# PIC32CZ4010CA80144 register map
Vendor: Microchip Technology; Series: PIC32CZCA80; File version: 0
CPU: CM7 r1p1, little endian, MPU, FPU, double-precision FPU, I-cache, D-cache, ITCM, DTCM, 3 interrupt priority bits, 222 interrupts
Registers are 32-bit, read-write, reset 0x0 unless marked. A register's access mark holds for its fields unless they carry their own. Offsets are from the block's base; [hi:lo] are bit positions.

## FCR — Flash Read Controller (FCR)
Base 0x44004000
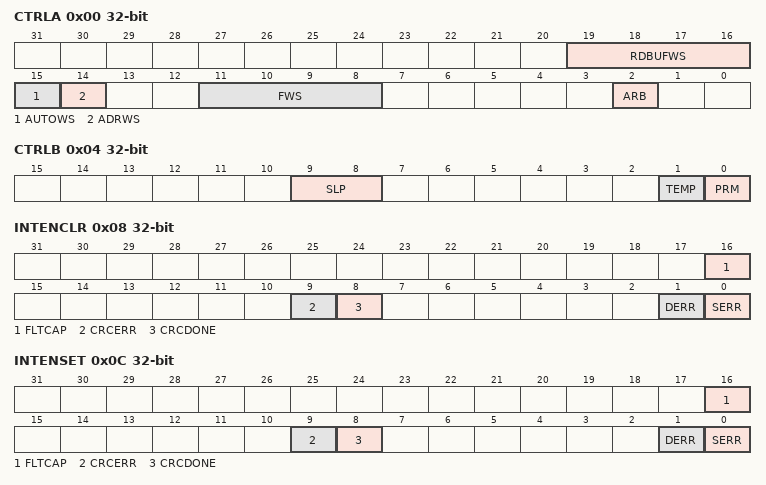
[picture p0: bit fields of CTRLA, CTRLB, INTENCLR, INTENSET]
0x00 CTRLA — Control A Register
  [19:16] RDBUFWS — Data returned from the Read Buffer match the Flash Wait States
  [15] AUTOWS — Automatic Wait State Enable.
  [14] ADRWS — Address Wait State Enable
  [11:8] FWS — Flash Access Time Defined in terms of AHB Clock Wait States
  [2] ARB — AHB Arbitration scheme
0x04 CTRLB — Control B Register
  [9:8] SLP — NVM Power Reduction Mode selection during System Standby Sleep
  [1] TEMP — NVM Operating Temperature Read Mode
  [0] PRM — Set NVM Power Reduction Mode
0x08 INTENCLR write-1-clears — Interrupt Enable Clear Register
  [16] FLTCAP — ECC Fault Capture Clear Enable
  [9] CRCERR — CRC Error Clear Enable
  [8] CRCDONE — CRC Calculation Done Clear Enable
  [1] DERR — ECC Double Error Detected Clear Enable
  [0] SERR — Flash SEC Interrupt Clear Enable
0x0C INTENSET write-1-sets — Interrupt Enable SET Register
  [16] FLTCAP — ECC Fault Capture Interrupt Set Enable
  [9] CRCERR — CRC Error Interrupt Set Enable
  [8] CRCDONE — CRC Calculation Done Set Enable
  [1] DERR — ECC Double Error Detected Set Enable
  [0] SERR — Flash Single Error Corrected Set Enable
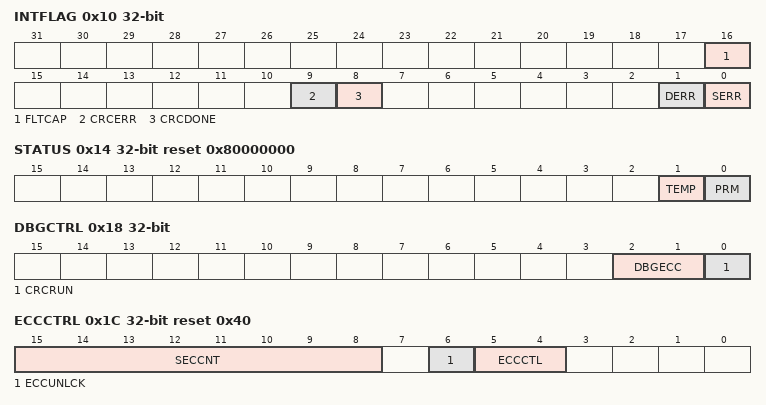
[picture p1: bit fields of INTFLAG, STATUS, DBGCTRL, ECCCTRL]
0x10 INTFLAG write-1-clears — Interrupt Flag Register
  [16] FLTCAP — ECC Fault Capture Flag
  [9] CRCERR — CRC Error Flag
  [8] CRCDONE — CRC Calculation Done Flag
  [1] DERR — ECC Double Error Detected Flag
  [0] SERR — Flash Single Error Corrected Flag
0x14 STATUS ro reset 0x80000000 — NVM Status Register
  [1] TEMP — NVM Operating Temperature Read Mode Status
  [0] PRM — NVM Power Reduction Mode Status
0x18 DBGCTRL — Debug Control Register
  [2:1] DBGECC — Debug ECC Mode
  [0] CRCRUN — CRC Debug Run
0x1C ECCCTRL reset 0x40 — ECC Control Register
  [15:8] SECCNT — Flash SEC Count
  [6] ECCUNLCK — NVM ECC Mode Control Unlock
  [5:4] ECCCTL — NVM ECC Mode Control- restricts one or more NVMOPs
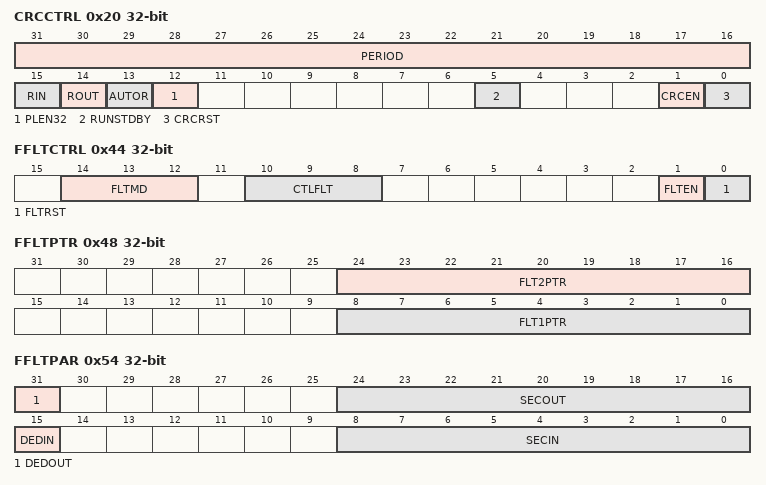
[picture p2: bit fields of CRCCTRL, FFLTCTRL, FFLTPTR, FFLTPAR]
0x20 CRCCTRL — CRC Control Register
  [31:16] PERIOD — Read Period in GCLK counts
  [15] RIN — CRC Reflected Input
  [14] ROUT — CRC Reflected Output
  [13] AUTOR — CRC Auto Repeat
  [12] PLEN32 — Polynomial Length Select
  [5] RUNSTDBY — CRC Run in Standby
  [1] CRCEN — Start CRC Calculation
  [0] CRCRST — CRC Reset
0x24 CRCPAUSE
  [0] PAUSE — CRC Pause
0x28 CRCMADR — CRC Message Address Register
  [27:0] CRCMADR — Message Start Address in Flash
0x2C CRCMLEN — CRC Message Length Register
  [23:0] CRCMLEN — Message Length in Bytes
0x30 CRCIV — CRC Initial Value Register
  [31:0] CRCIV — CRC Initial Value
0x34 CRCACC ro — CRC Accumulator Register
  [31:0] CRCACC — CRC Accumulator Result
0x38 CRCPOLY — CRC Polynomial Register
  [31:0] CRCPOLY — CRC Polynomial Coefficients for LFSR
0x3C CRCFXOR — CRC Final XOR Register
  [31:0] CRCFXOR — CRC Final XOR
0x40 CRCSUM — CRC Checksum Register
  [31:0] CRCSUM — CRC Checksum
0x44 FFLTCTRL — Flash ECC Fault Control Register
  [14:12] FLTMD — Fault Mode Control
  [10:8] CTLFLT — ECC/Parity Control Fault bits
  [1] FLTEN — ECC Fault Enable bit
  [0] FLTRST — Fault Reset
0x48 FFLTPTR — Flash ECC Fault Pointer Register
  [24:16] FLT2PTR — Fault 2 Injection Pointer
  [8:0] FLT1PTR — Fault 1 Injection Pointer
0x4C FFLTADR — Flash Fault Address Register
  [27:0] FLTADR — Fault Inject Mode - Physical Address
0x50 FFLTCAP ro — Flash Fault Capture Address Register
  [27:0] FLTADR — Fault capture Mode - Physical Address
0x54 FFLTPAR ro — Flash ECC Fault Parity Register
  [31] DEDOUT — The Calculated Overall Parity used in Double Error Detection
  [24:16] SECOUT — The Calculated Single Error Parity bits
  [15] DEDIN — The Overall Parity from Flash
  [8:0] SECIN — The Single Error Parity bits from Flash
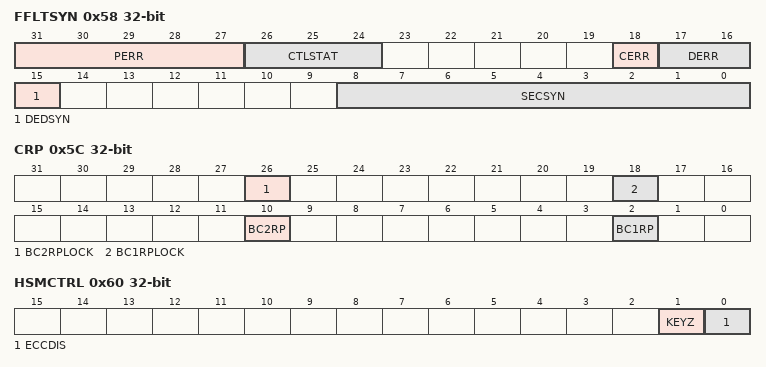
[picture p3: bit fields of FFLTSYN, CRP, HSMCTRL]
0x58 FFLTSYN ro — Flash ECC Fault Syndrome Register
  [31:27] PERR — Per Word Parity Error Status
  [26:24] CTLSTAT — Parity vs ECC Control Status
  [18] CERR — ECC Control bit Error
  [17:16] DERR — Double Error Detected & Single Error Corrected
  [15] DEDSYN — DED Syndrome
  [8:0] SECSYN — Single Error Correction Syndrome
0x5C CRP — CFM Page Read Protect Register
  [26] BC2RPLOCK — Boot Configuration Page 2 RP Lock Bit
  [18] BC1RPLOCK — Boot Configuration Page 1 RP Lock Bit
  [10] BC2RP — Boot Configuration Page 2 Read Protect Bit
  [2] BC1RP — Boot Configuration Page 1 Read Protect Bit
0x60 HSMCTRL — HSM CFM PAGES Control Register
  [1] KEYZ — Flash Key Locations read
  [0] ECCDIS — ECC Disable for HSM Pages in CFM

## Notices in the file
Copyright (c) 2026 Microchip Technology Inc.
SPDX-License-Identifier: Apache-2.0
Licensed under the Apache License, Version 2.0 (the "License");
you may not use this file except in compliance with the License.
You may obtain a copy of the License at
http://www.apache.org/licenses/LICENSE-2.0
Unless required by applicable law or agreed to in writing, software
distributed under the License is distributed on an "AS IS" BASIS,
WITHOUT WARRANTIES OR CONDITIONS OF ANY KIND, either express or implied.
See the License for the specific language governing permissions and
limitations under the License.
